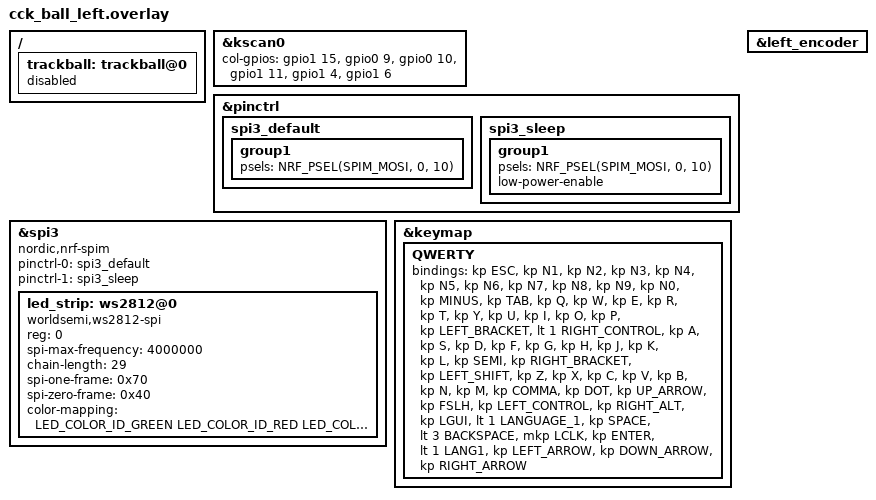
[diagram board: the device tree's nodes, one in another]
/*
 * Copyright (c) 2020 ZMK Contributors
 *
 * SPDX-License-Identifier: MIT
 */

#include "cck_ball.dtsi"

&kscan0 {
	col-gpios
		= <&gpio1 15 GPIO_ACTIVE_HIGH>
        , <&gpio0 9 GPIO_ACTIVE_HIGH>
        , <&gpio0 10 GPIO_ACTIVE_HIGH>
        , <&gpio1 11 GPIO_ACTIVE_HIGH>
        , <&gpio1 4 GPIO_ACTIVE_HIGH>
        , <&gpio1 6 GPIO_ACTIVE_HIGH>
		;
};

//RGB bus

&pinctrl {
    spi3_default: spi3_default {
        group1 {
            psels = <NRF_PSEL(SPIM_MOSI, 0, 10)>;
        };
    };

    spi3_sleep: spi3_sleep {
        group1 {
            psels = <NRF_PSEL(SPIM_MOSI, 0, 10)>;
            low-power-enable;
        };
    };
};

&spi3 {
    compatible = "nordic,nrf-spim";
    status = "okay";

    pinctrl-0 = <&spi3_default>;
    pinctrl-1 = <&spi3_sleep>;
    pinctrl-names = "default", "sleep";

    led_strip: ws2812@0 {
        compatible = "worldsemi,ws2812-spi";

        /* SPI */
        reg = <0>; /* ignored, but necessary for SPI bindings */
        spi-max-frequency = <4000000>;

        /* WS2812 */
        chain-length = <29>; /* number of LEDs */
        spi-one-frame = <0x70>;
        spi-zero-frame = <0x40>;
        color-mapping = <LED_COLOR_ID_GREEN
                         LED_COLOR_ID_RED
                         LED_COLOR_ID_BLUE>;
    };
};

// enable left encoder
&left_encoder {
	status = "okay";
};

// trackball ノードを無効化（左側にはトラックボールがないため）
// これにより、scroll_listener がエラーにならない
/ {
    trackball: trackball@0 {
        status = "disabled";
    };
};

// 左側はLANG1を使用
&keymap {
    QWERTY {
        bindings = <
&kp ESC              &kp N1         &kp N2            &kp N3            &kp N4     &kp N5           &kp N6     &kp N7     &kp N8       &kp N9          &kp N0          &kp MINUS
&kp TAB              &kp Q          &kp W             &kp E             &kp R      &kp T            &kp Y      &kp U      &kp I        &kp O           &kp P           &kp LEFT_BRACKET
&lt 1 RIGHT_CONTROL  &kp A          &kp S             &kp D             &kp F      &kp G            &kp H      &kp J      &kp K        &kp L           &kp SEMI        &kp RIGHT_BRACKET
&kp LEFT_SHIFT       &kp Z          &kp X             &kp C             &kp V      &kp B            &kp N      &kp M      &kp COMMA    &kp DOT         &kp UP_ARROW    &kp FSLH
&kp LEFT_CONTROL     &kp RIGHT_ALT  &kp LGUI  &lt 1 LANGUAGE_1  &kp SPACE  &lt 3 BACKSPACE  &mkp LCLK  &kp ENTER  &lt 1 LANG1  &kp LEFT_ARROW  &kp DOWN_ARROW  &kp RIGHT_ARROW
        >;
    };
};
